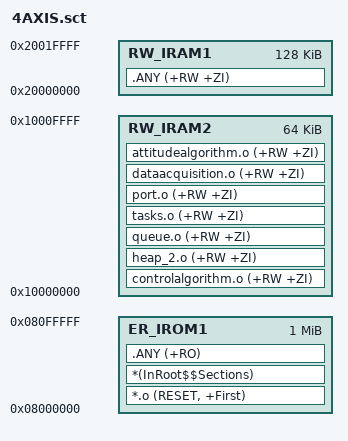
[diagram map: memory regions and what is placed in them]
; *************************************************************
; *** Scatter-Loading Description File generated by uVision ***
; *************************************************************

LR_IROM1 0x08000000 0x00100000  {    ; load region size_region
  ER_IROM1 0x08000000 0x00100000  {  ; load address = execution address
   *.o (RESET, +First)
   *(InRoot$$Sections)
   .ANY (+RO)
  }
  RW_IRAM1 0x20000000 0x00020000  {  ; RW data
   .ANY (+RW +ZI)
  }
  RW_IRAM2 0x10000000 0x00010000  {
;   croutine.o (+RW +ZI)
;   list.o (+RW +ZI)
;   timers.o (+RW +ZI)  
   controlalgorithm.o (+RW +ZI)  
   heap_2.o (+RW +ZI)
   queue.o (+RW +ZI)
   tasks.o (+RW +ZI)
   port.o (+RW +ZI)
   dataacquisition.o (+RW +ZI)
   attitudealgorithm.o (+RW +ZI)
  }
}

